# ATtiny87 device description
Architecture: AVR8; Family: tinyAVR
Registers are 8-bit, access not given, no defined reset value unless marked. A register's access mark holds for its fields unless they carry their own. Offsets are from the block's base; [hi:lo] are bit positions.

## LINUART — Local Interconnect Network
Instances: LINUART 0x00
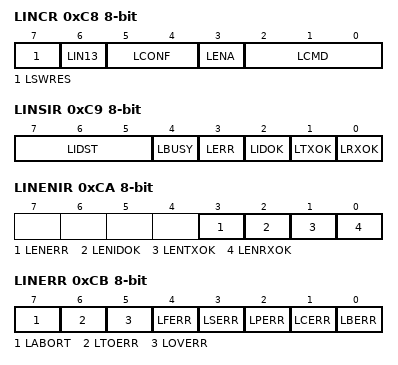
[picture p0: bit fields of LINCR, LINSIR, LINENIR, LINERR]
0xC8 LINCR — LIN Control Register
  [7] LSWRES — Software Reset
  [6] LIN13 — LIN Standard
  [5:4] LCONF — LIN Configuration bits
  [3] LENA — LIN or UART Enable
  [2:0] LCMD — LIN Command and Mode bits
0xC9 LINSIR — LIN Status and Interrupt Register
  [7:5] LIDST — Identifier Status bits
  [4] LBUSY — Busy Signal
  [3] LERR — Error Interrupt
  [2] LIDOK — Identifier Interrupt
  [1] LTXOK — Transmit Performed Interrupt
  [0] LRXOK — Receive Performed Interrupt
0xCA LINENIR — LIN Enable Interrupt Register
  [3] LENERR — Enable Error Interrupt
  [2] LENIDOK — Enable Identifier Interrupt
  [1] LENTXOK — Enable Transmit Performed Interrupt
  [0] LENRXOK — Enable Receive Performed Interrupt
0xCB LINERR — LIN Error Register
  [7] LABORT — Abort Flag
  [6] LTOERR — Frame Time Out Error Flag
  [5] LOVERR — Overrun Error Flag
  [4] LFERR — Framing Error Flag
  [3] LSERR — Synchronization Error Flag
  [2] LPERR — Parity Error Flag
  [1] LCERR — Checksum Error Flag
  [0] LBERR — Bit Error Flag
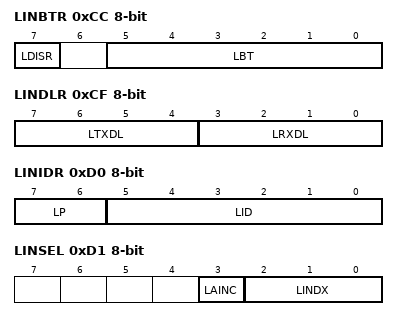
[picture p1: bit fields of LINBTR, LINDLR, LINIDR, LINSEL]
0xCC LINBTR — LIN Bit Timing Register
  [7] LDISR — Disable Bit Timing Resynchronization
  [5:0] LBT — LIN Bit Timing bits
0xCD LINBRRL — LIN Baud Rate Low Register
  [7:0] LDIV
0xCE LINBRRH — LIN Baud Rate High Register
  [3:0] LDIV (bit 8 of the value upward)
0xCF LINDLR — LIN Data Length Register
  [7:4] LTXDL — LIN Transmit Data Length bits
  [3:0] LRXDL — LIN Receive Data Length bits
0xD0 LINIDR — LIN Identifier Register
  [7:6] LP — Parity bits
  [5:0] LID — Identifier bit 5 or Data Length bits
0xD1 LINSEL — LIN Data Buffer Selection Register
  [3] LAINC — Auto Increment of Data Buffer Index (Active Low)
  [2:0] LINDX — FIFO LIN Data Buffer Index bits
0xD2 LINDAT — LIN Data Register
  [7:0] LDATA

## USI — Universal Serial Interface
Instances: USI 0x00
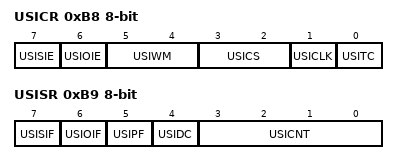
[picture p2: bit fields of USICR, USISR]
0xB8 USICR — USI Control Register
  [7] USISIE — Start Condition Interrupt Enable
  [6] USIOIE — Counter Overflow Interrupt Enable
  [5:4] USIWM — USI Wire Mode Bits
    0=NORMAL_OPERATION; 1=THREE_WIRE_MODE; 2=TWO_WIRE_MODE; 3=TWO_WIRE_MODE_HELD_LOW
  [3:2] USICS — USI Clock Source Select Bits
  [1] USICLK — Clock Strobe
  [0] USITC — Toggle Clock Port Pin
0xB9 USISR — USI Status Register
  [7] USISIF — Start Condition Interrupt Flag
  [6] USIOIF — Counter Overflow Interrupt Flag
  [5] USIPF — Stop Condition Flag
  [4] USIDC — Data Output Collision
  [3:0] USICNT — USI Counter Value Bits
0xBA USIDR — USI Data Register
0xBB USIBR — USI Buffer Register
0xBC USIPP bits used 0 — USI Pin Position

## TC0 (TC8_ASYNC module) — Timer/Counter, 8-bit Async
Instances: TC0 0x00
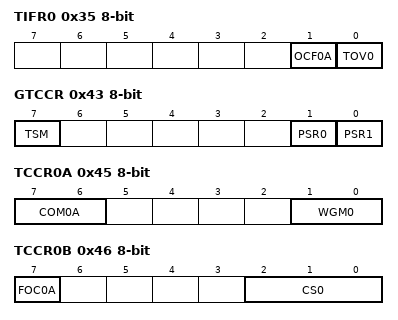
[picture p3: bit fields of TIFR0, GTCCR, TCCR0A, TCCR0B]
0x35 TIFR0 — Timer/Counter0 Interrupt Flag Register
  [1] OCF0A — Output Compare Flag 0A
  [0] TOV0 — Timer/Counter0 Overflow Flag
0x43 GTCCR — General Timer Counter Control register
  [7] TSM — Timer/Counter Synchronization Mode
  [1] PSR0 — Prescaler Reset Asynchronous 8-bit Timer/Counter0
  [0] PSR1 — Prescaler Reset Synchronous 16-bit Timer/Counter1
0x45 TCCR0A — Timer/Counter0 Control Register A
  [7:6] COM0A — Compare Output Mode bits
  [1:0] WGM0 — Waveform Generation Mode bits
0x46 TCCR0B — Timer/Counter0 Control Register B
  [7] FOC0A — Force Output Compare A
  [2:0] CS0 — Clock Select bits
    0=NO_CLOCK_SOURCE_STOPPED; 1=RUNNING_NO_PRESCALING; 2=RUNNING_CLK_8; 3=RUNNING_CLK_32; 4=RUNNING_CLK_64; 5=RUNNING_CLK_128; 6=RUNNING_CLK_256; 7=RUNNING_CLK_1024
0x47 TCNT0 — Timer/Counter0
0x48 OCR0A — Timer/Counter0 Output Compare Register A
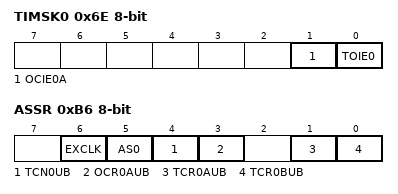
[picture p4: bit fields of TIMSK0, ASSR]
0x6E TIMSK0 — Timer/Counter0 Interrupt Mask register
  [1] OCIE0A — Timer/Counter0 Output Compare Match A Interrupt Enable
  [0] TOIE0 — Timer/Counter0 Overflow Interrupt Enable
0xB6 ASSR — Asynchronous Status Register
  [6] EXCLK — Enable External Clock Input
  [5] AS0 — Asynchronous Timer/Counter0
  [4] TCN0UB — Timer/Counter0 Update Busy
  [3] OCR0AUB — Output Compare Register 0A Update Busy
  [1] TCR0AUB — Timer/Counter0 Control Register A Update Busy
  [0] TCR0BUB — Timer/Counter0 Control Register B Update Busy
